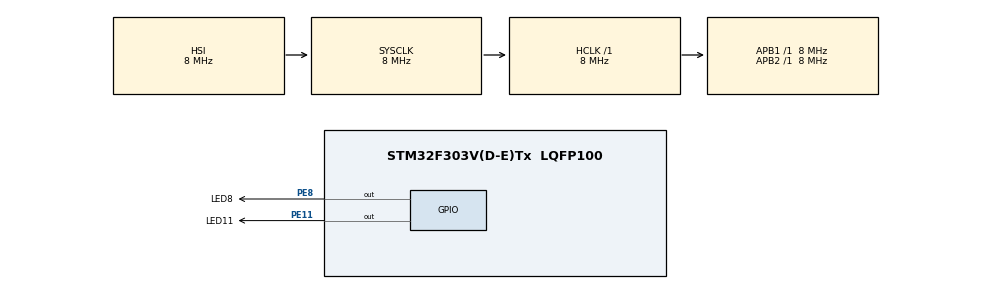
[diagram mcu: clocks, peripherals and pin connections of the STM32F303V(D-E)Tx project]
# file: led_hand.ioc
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Mcu.Family=STM32F3
Mcu.Name=STM32F303V(D-E)Tx
Mcu.Package=LQFP100
NVIC.PriorityGroup=NVIC_PRIORITYGROUP_4
PA13.Mode=Serial_Wire
PA13.Signal=SYS_JTMS-SWDIO
PA14.Mode=Serial_Wire
PA14.Signal=SYS_JTCK-SWCLK
PE11.GPIO_Label=LED11
PE11.Signal=GPIO_Output
PE8.GPIO_Label=LED8
PE8.GPIO_ModeDefaultOutputPP=GPIO_MODE_OUTPUT_PP
PE8.GPIO_Speed=GPIO_SPEED_FREQ_HIGH
PE8.Signal=GPIO_Output
ProjectManager.HeapSize=0x200
ProjectManager.StackSize=0x400
ProjectManager.TargetToolchain=STM32CubeIDE
RCC.AHBFreq_Value=8000000
RCC.APB1Freq_Value=8000000
RCC.APB2Freq_Value=8000000
RCC.CortexFreq_Value=8000000
RCC.HSE_VALUE=8000000
RCC.HSI_VALUE=8000000
RCC.LSE_VALUE=32768
RCC.SYSCLKFreq_VALUE=8000000
RCC.USBFreq_Value=16000000
board=custom

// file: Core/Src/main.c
/* USER CODE BEGIN Header */
/**
  ******************************************************************************
  * @file           : main.c
  * @brief          : Main program body
  ******************************************************************************
  * @attention
  *
  * Copyright (c) 2022 STMicroelectronics.
  * All rights reserved.
  *
  * This software is licensed under terms that can be found in the LICENSE file
  * in the root directory of this software component.
  * If no LICENSE file comes with this software, it is provided AS-IS.
  *
  ******************************************************************************
  */
/* USER CODE END Header */
#include "main.h"

void SystemClock_Config(void);
static void MX_GPIO_Init(void);

int main(void)
{

  /* MCU Configuration--------------------------------------------------------*/

  /* Reset of all peripherals, Initializes the Flash interface and the Systick. */
  HAL_Init();//HAL初始化库函数

  /* USER CODE BEGIN Init */
  __HAL_RCC_GPIOE_CLK_ENABLE();//给GPIO某一类引脚设置时钟使能  RCC是管理系统复位和时钟控制的
  /* USER CODE END Init */

  /* Configure the system clock */
  SystemClock_Config();//配置时钟

  /* Initialize all configured peripherals */
  MX_GPIO_Init();//初始化GPIO

  /* Infinite loop */
  /* USER CODE BEGIN WHILE */
  while (1)
  {
	  HAL_GPIO_WritePin(LED11_GPIO_Port, LED11_Pin, GPIO_PIN_RESET);
	  HAL_GPIO_WritePin(LED8_GPIO_Port, LED8_Pin, GPIO_PIN_RESET);
	  HAL_Delay(250);
	  HAL_GPIO_WritePin(LED11_GPIO_Port, LED11_Pin, GPIO_PIN_SET);
	  HAL_GPIO_WritePin(LED8_GPIO_Port, LED8_Pin, GPIO_PIN_SET);
	  HAL_Delay(250);
    /* USER CODE END WHILE */

  }
}

void SystemClock_Config(void)
{
  RCC_OscInitTypeDef RCC_OscInitStruct = {0};
  RCC_ClkInitTypeDef RCC_ClkInitStruct = {0};

  /** Initializes the RCC Oscillators according to the specified parameters
  * in the RCC_OscInitTypeDef structure.
  */
  RCC_OscInitStruct.OscillatorType = RCC_OSCILLATORTYPE_HSI;
  RCC_OscInitStruct.HSIState = RCC_HSI_ON;
  RCC_OscInitStruct.HSICalibrationValue = RCC_HSICALIBRATION_DEFAULT;
  RCC_OscInitStruct.PLL.PLLState = RCC_PLL_NONE;
  if (HAL_RCC_OscConfig(&RCC_OscInitStruct) != HAL_OK)
  {
    Error_Handler();
  }

  /** Initializes the CPU, AHB and APB buses clocks
  */
  RCC_ClkInitStruct.ClockType = RCC_CLOCKTYPE_HCLK|RCC_CLOCKTYPE_SYSCLK
                              |RCC_CLOCKTYPE_PCLK1|RCC_CLOCKTYPE_PCLK2;
  RCC_ClkInitStruct.SYSCLKSource = RCC_SYSCLKSOURCE_HSI;
  RCC_ClkInitStruct.AHBCLKDivider = RCC_SYSCLK_DIV1;
  RCC_ClkInitStruct.APB1CLKDivider = RCC_HCLK_DIV1;
  RCC_ClkInitStruct.APB2CLKDivider = RCC_HCLK_DIV1;

  if (HAL_RCC_ClockConfig(&RCC_ClkInitStruct, FLASH_LATENCY_0) != HAL_OK)
  {
    Error_Handler();
  }
}

static void MX_GPIO_Init(void)
{
  GPIO_InitTypeDef GPIO_InitStruct = {0};

  /* GPIO Ports Clock Enable */
  __HAL_RCC_GPIOE_CLK_ENABLE();
  __HAL_RCC_GPIOA_CLK_ENABLE();

  /*Configure GPIO pin Output Level */
  HAL_GPIO_WritePin(GPIOE, LED8_Pin|LED11_Pin, GPIO_PIN_RESET);

  /*Configure GPIO pin : LED8_Pin */
  GPIO_InitStruct.Pin = LED8_Pin;
  GPIO_InitStruct.Mode = GPIO_MODE_OUTPUT_PP;
  GPIO_InitStruct.Pull = GPIO_NOPULL;
  GPIO_InitStruct.Speed = GPIO_SPEED_FREQ_HIGH;
  HAL_GPIO_Init(LED8_GPIO_Port, &GPIO_InitStruct);

  /*Configure GPIO pin : LED11_Pin */
  GPIO_InitStruct.Pin = LED11_Pin;
  GPIO_InitStruct.Mode = GPIO_MODE_OUTPUT_PP;
  GPIO_InitStruct.Pull = GPIO_NOPULL;
  GPIO_InitStruct.Speed = GPIO_SPEED_FREQ_LOW;
  HAL_GPIO_Init(LED11_GPIO_Port, &GPIO_InitStruct);

}

void Error_Handler(void)
{
  __disable_irq();
  while (1)
  {
  }
}
